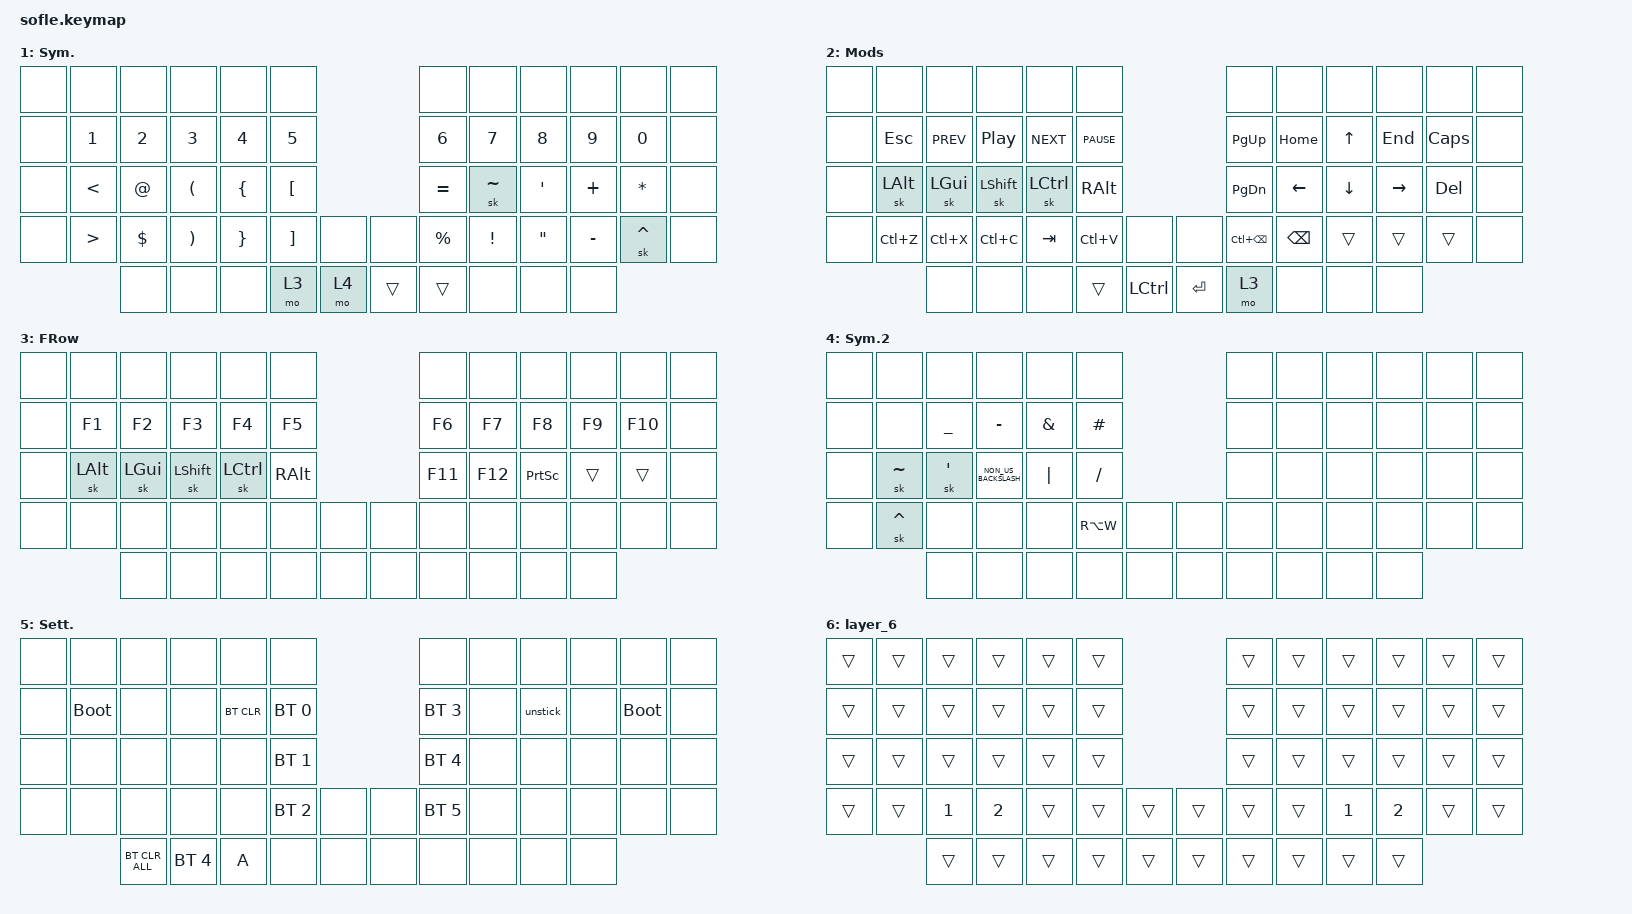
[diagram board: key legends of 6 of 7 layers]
/*
 * Copyright (c) 2020 duckyb
 *
 * SPDX-License-Identifier: MIT
 */

#include <behaviors.dtsi>
#include <dt-bindings/zmk/bt.h>
#include <dt-bindings/zmk/keys.h>

// Layer definitions

#define BASE 0
#define SYM 1
#define EXT 2
#define FNC 3
#define SYM2 4
#define ACCENT 5
#define SETTINGS 6

// -----------------

&sk {
    // don't release mods on other mods presses

    ignore-modifiers;
};

/ {
    behaviors {
        // Enables holding the first mod-tap key by performing a tap-release-hold sequence.
        // To use it: "&qt KEYCODE1 KEYCODE2"

        qt: quick_tap {
            compatible = "zmk,behavior-hold-tap";
            label = "QUICK_TAP";
            #binding-cells = <2>;
            flavor = "hold-preferred";
            tapping-term-ms = <200>;
            quick-tap-ms = <200>;
            bindings = <&kp>, <&kp>;
        };
    };

    macros {
        // sometimes my device thinks a modifier is being held down
        // pressing all modifiers fixes it.

        unstick: unstick {
            label = "ZM_unstick";
            compatible = "zmk,behavior-macro";
            #binding-cells = <0>;
            bindings = <&kp LSHIFT &kp RSHIFT &kp LCTRL &kp RCTRL &kp LALT &kp RALT &kp LGUI &kp RGUI>;
        };

        caret: caret {
            compatible = "zmk,behavior-macro";
            #binding-cells = <0>;
            bindings = <&sk LS(NUMBER_6) &kp E>;
            label = "CARET";
        };

        quote: quote {
            compatible = "zmk,behavior-macro";
            #binding-cells = <0>;
            bindings = <&sk LS(SINGLE_QUOTE) &kp E>;
            label = "QUOTE";
        };

        tilde: tilde {
            compatible = "zmk,behavior-macro";
            #binding-cells = <0>;
            bindings = <&sk TILDE &kp A>;
            label = "TILDE";
        };

        accent: accent {
            compatible = "zmk,behavior-macro";
            #binding-cells = <0>;
            bindings = <&sk GRAVE &kp A>;
            label = "ACCENT";
        };

        crtlAlt: crtlAlt {
            compatible = "zmk,behavior-macro";
            #binding-cells = <0>;
            bindings = <&kp RCTRL &kp LEFT_ALT>;
            label = "CRTLALT";
        };
    };

    combos {
        compatible = "zmk,combos";

        // both right thumb keys

        combo_accent {
            timeout-ms = <200>;
            key-positions = <54 56>;
            bindings = <&mo 0>;
        };

        // internal-left & external-right thumb keys

        combo_sym2 {
            timeout-ms = <200>;
            key-positions = <55 56>;
            bindings = <&mo 4>;
        };

        // both left thumb keys

        combo_settings {
            timeout-ms = <200>;
            key-positions = <53 54>;
            bindings = <&mo 5>;
        };

        // left index & middle fingers (home-row)
        // hold control & space for Adobe workflow

        Backspace {
            bindings = <&kp BACKSPACE>;
            key-positions = <28 29>;
        };

        Tab {
            bindings = <&kp TAB>;
            key-positions = <17 16>;
        };

        Esc {
            bindings = <&kp ESCAPE>;
            key-positions = <13 14>;
        };

        Ctrl-stiky {
            bindings = <&sk LEFT_CONTROL>;
            key-positions = <37 38>;
        };

        Shift_sticky {
            bindings = <&sk LEFT_ALT>;
            key-positions = <25 26>;
        };

        Play-Pause {
            bindings = <&kp C_PLAY_PAUSE>;
            key-positions = <15 16>;
        };

        Enter {
            bindings = <&kp RETURN>;
            key-positions = <41 40 39>;
        };

        Linguagem {
            bindings = <&kp LG(SPACE)>;
            key-positions = <53 54 55 56>;
        };

        enter2 {
            bindings = <&kp RETURN>;
            key-positions = <44 45 46>;
        };

        backspace2 {
            bindings = <&kp BACKSPACE>;
            key-positions = <30 31>;
        };

        ControlAlt {
            bindings = <&crtlAlt>;
            key-positions = <25 13 37>;
        };

        PrintScreem {
            bindings = <&kp PRINTSCREEN>;
            key-positions = <17 13>;
        };

        FormatarVS {
            bindings = <&kp LA(LS(F))>;
            key-positions = <37 41>;
        };

        Terminal {
            bindings = <&kp LC(GRAVE)>;
            key-positions = <37 29>;
        };

        CtrlB {
            bindings = <&kp LC(B)>;
            key-positions = <37 17>;
        };

        Comment {
            bindings = <&kp LC(SLASH)>;
            key-positions = <25 29>;
        };
    };

    keymap {
        compatible = "zmk,keymap";

        // Base alpha layer

        default_layer {
            label = "Base";
            bindings = <
&kp ESC           &kp NUMBER_1  &kp NUMBER_2   &kp NUMBER_3  &kp NUMBER_4  &kp N5                                 &kp NUMBER_6  &kp N7  &kp N8          &kp N9   &kp N0         &kt GRAVE
&none             &kp Q         &kp W          &kp E         &kp R         &kp T                                  &kp Y         &kp U   &kp I           &kp O    &kp P          &none
&kp LEFT_ALT      &kp A         &kp S          &kp D         &kp F         &kp G                                  &kp H         &kp J   &kp K           &kp L    &kp QMARK      &none
&kp LEFT_CONTROL  &kp Z         &kp X          &kp C         &kp V         &kp B   &kp K_MUTE          &kp B      &kp N         &kp M   &kp COMMA       &kp DOT  &kp SEMICOLON  &none
                                &kp LC(ENTER)  &none         &none         &mo 2   &qt LSHIFT SPACE    &kp SPACE  &mo 1         &mo 4   &kp UNDERSCORE
            >;

            sensor-bindings =
                <&inc_dec_kp C_VOLUME_UP C_VOLUME_DOWN>,
                <&inc_dec_kp C_AC_SCROLL_UP C_AC_SCROLL_DOWN>;
        };

        // Numbers and high frequency symbols

        sym_layer {
            label = "Sym.";
            bindings = <
&none  &none             &none        &none                  &none            &none                               &none         &none            &none              &none      &none         &none
&none  &kp N1            &kp N2       &kp N3                 &kp NUMBER_4     &kp N5                              &kp NUMBER_6  &kp N7           &kp N8             &kp N9     &kp N0        &none
&none  &kp LESS_THAN     &kp AT_SIGN  &kp LEFT_PARENTHESIS   &kp LEFT_BRACE   &kp LEFT_BRACKET                    &kp EQUAL     &sk TILDE        &kp SINGLE_QUOTE   &kp PLUS   &kp ASTERISK  &none
&none  &kp GREATER_THAN  &kp DOLLAR   &kp RIGHT_PARENTHESIS  &kp RIGHT_BRACE  &kp RIGHT_BRACKET  &none    &none   &kp PERCENT   &kp EXCLAMATION  &kp DOUBLE_QUOTES  &kp MINUS  &sk CARET     &none
                         &none        &none                  &none            &mo 3              &mo 4    &trans  &trans        &none            &none              &none
            >;
        };

        // Main modifiers and arrow keys

        ext_layer {
            label = "Mods";
            bindings = <
&none  &none      &none       &none       &none       &none                                &none         &none     &none     &none      &none     &none
&none  &kp ESC    &kp C_PREV  &kp C_PP    &kp C_NEXT  &kp C_PAUSE                          &kp PG_UP     &kp HOME  &kp UP    &kp END    &kp CAPS  &none
&none  &sk LALT   &sk LGUI    &sk LSHIFT  &sk LCTRL   &kp RALT                             &kp PG_DN     &kp LEFT  &kp DOWN  &kp RIGHT  &kp DEL   &none
&none  &kp LC(Z)  &kp LC(X)   &kp LC(C)   &kp TAB     &kp LC(V)    &none        &none      &kp LC(BSPC)  &kp BSPC  &trans    &trans     &trans    &none
                  &none       &none       &none       &trans       &kp LCTRL    &kp ENTER  &mo 3         &none     &none     &none
            >;
        };

        // Function keys with modifiers

        fnc_layer {
            label = "FRow";
            bindings = <
&none  &none     &none     &none       &none      &none                     &none    &none    &none            &none   &none    &none
&none  &kp F1    &kp F2    &kp F3      &kp F4     &kp F5                    &kp F6   &kp F7   &kp F8           &kp F9  &kp F10  &none
&none  &sk LALT  &sk LGUI  &sk LSHIFT  &sk LCTRL  &kp RALT                  &kp F11  &kp F12  &kp PRINTSCREEN  &trans  &trans   &none
&none  &none     &none     &none       &none      &none     &none    &none  &none    &none    &none            &none   &none    &none
                 &none     &none       &none      &none     &none    &none  &none    &none    &none            &none
            >;
        };

        // Low frequency symbols

        symbols_2_layer {
            label = "Sym.2";
            bindings = <
&none  &none      &none             &none                 &none          &none                      &none  &none  &none  &none  &none  &none
&none  &none      &kp UNDERSCORE    &kp MINUS             &kp AMPERSAND  &kp POUND                  &none  &none  &none  &none  &none  &none
&none  &sk TILDE  &sk SINGLE_QUOTE  &kp NON_US_BACKSLASH  &kp PIPE       &kp SLASH                  &none  &none  &none  &none  &none  &none
&none  &sk CARET  &none             &none                 &none          &kp RA(W)  &none    &none  &none  &none  &none  &none  &none  &none
                  &none             &none                 &none          &none      &none    &none  &none  &none  &none  &none
            >;
        };

        // Used to type regional accents
        // Used to change the keyboard's settings

        settings_layer {
            label = "Sett.";
            bindings = <
&none  &none        &none           &none         &none       &none                         &none         &none  &none     &none  &none        &none
&none  &bootloader  &none           &none         &bt BT_CLR  &bt BT_SEL 0                  &bt BT_SEL 3  &none  &unstick  &none  &bootloader  &none
&none  &none        &none           &none         &none       &bt BT_SEL 1                  &bt BT_SEL 4  &none  &none     &none  &none        &none
&none  &none        &none           &none         &none       &bt BT_SEL 2  &none    &none  &bt BT_SEL 5  &none  &none     &none  &none        &none
                    &bt BT_CLR_ALL  &bt BT_SEL 4  &kp A       &none         &none    &none  &none         &none  &none     &none
            >;
        };

        layer_6 {
            bindings = <
&trans  &trans  &trans        &trans        &trans  &trans                    &trans  &trans  &trans        &trans        &trans  &trans
&trans  &trans  &trans        &trans        &trans  &trans                    &trans  &trans  &trans        &trans        &trans  &trans
&trans  &trans  &trans        &trans        &trans  &trans                    &trans  &trans  &trans        &trans        &trans  &trans
&trans  &trans  &kp NUMBER_1  &kp NUMBER_2  &trans  &trans  &trans    &trans  &trans  &trans  &kp NUMBER_1  &kp NUMBER_2  &trans  &trans
                &trans        &trans        &trans  &trans  &trans    &trans  &trans  &trans  &trans        &trans
            >;
        };
    };
};
